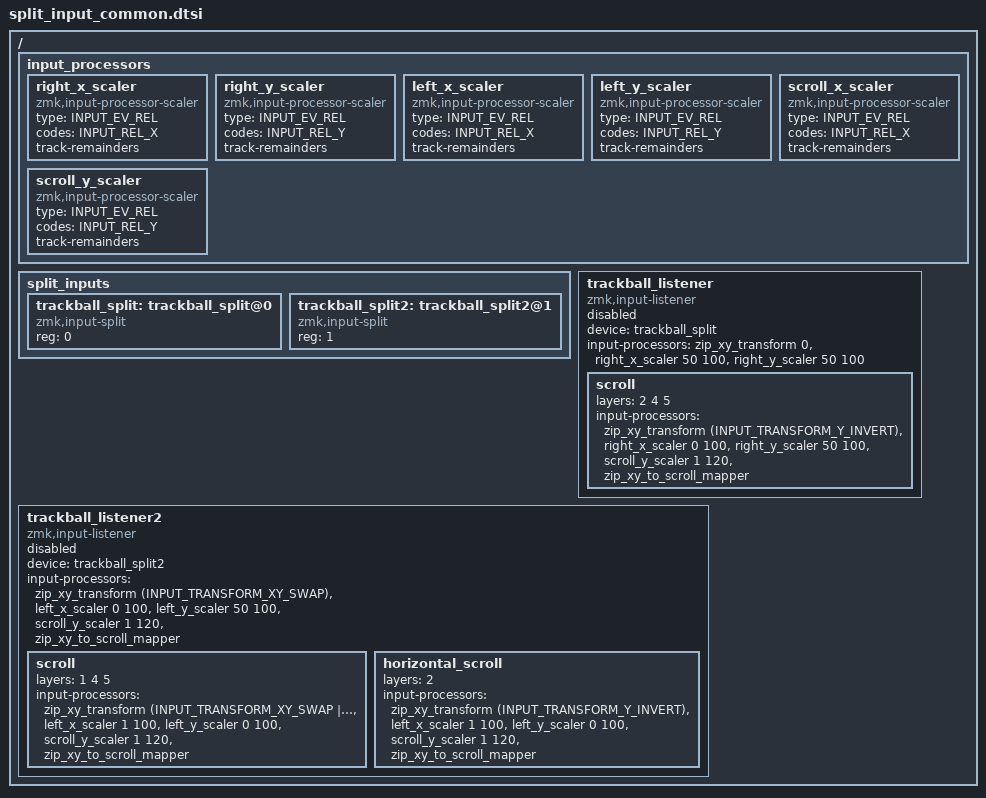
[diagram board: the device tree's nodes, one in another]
#include <dt-bindings/zmk/input_transform.h>
#include <input/processors.dtsi>
#include <zephyr/dt-bindings/input/input-event-codes.h>

#define WIN 1
#define SYMBOLS 2
#define NUMBERS 18
#define NAV 4
#define FUNCTION 5
#define BLUETOOTH 6
#define MOUSE 7
#define CLICK 8
#define SCRL 9
#define BIRO 10

/ {
  // カスタムInput Processors定義
  input_processors {
    // 右手トラックボール用（左45度+手前15度傾斜補正）
    right_x_scaler: right_x_scaler {
      compatible = "zmk,input-processor-scaler";
      #input-processor-cells = <2>;
      type = <INPUT_EV_REL>;
      codes = <INPUT_REL_X>;
      track-remainders;
    };
    
    right_y_scaler: right_y_scaler {
      compatible = "zmk,input-processor-scaler";
      #input-processor-cells = <2>;
      type = <INPUT_EV_REL>;
      codes = <INPUT_REL_Y>;
      track-remainders;
    };
    
    // 左手トラックボール用（同じ傾斜補正）
    left_x_scaler: left_x_scaler {
      compatible = "zmk,input-processor-scaler";
      #input-processor-cells = <2>;
      type = <INPUT_EV_REL>;
      codes = <INPUT_REL_X>;
      track-remainders;
    };
    
    left_y_scaler: left_y_scaler {
      compatible = "zmk,input-processor-scaler";
      #input-processor-cells = <2>;
      type = <INPUT_EV_REL>;
      codes = <INPUT_REL_Y>;
      track-remainders;
    };
    
    // スクロール用スケーラー（より敏感に）
    scroll_x_scaler: scroll_x_scaler {
      compatible = "zmk,input-processor-scaler";
      #input-processor-cells = <2>;
      type = <INPUT_EV_REL>;
      codes = <INPUT_REL_X>;
      track-remainders;
    };
    
    scroll_y_scaler: scroll_y_scaler {
      compatible = "zmk,input-processor-scaler";
      #input-processor-cells = <2>;
      type = <INPUT_EV_REL>;
      codes = <INPUT_REL_Y>;
      track-remainders;
    };
  };

  split_inputs {
    #address-cells = <1>;
    #size-cells = <0>;

    trackball_split: trackball_split@0 {
      compatible = "zmk,input-split";
      reg = <0>;
    };
    trackball_split2: trackball_split2@1 {
      compatible = "zmk,input-split";
      reg = <1>;
    };
  };

  // 右手：カーソル移動用トラックボール（傾斜補正付き）
  trackball_listener: trackball_listener {
    compatible = "zmk,input-listener";
    status = "disabled";
    device = <&trackball_split>;
    
    // デフォルト: 傾斜補正 + Y軸反転
    // 注意: 右手は左45度+手前15度傾斜
    input-processors = <&zip_xy_transform 0>,
                      <&right_x_scaler 50 100>,  // X軸: 70.7% → 100%補正
                      <&right_y_scaler 50 100>;  // Y軸: 96.6% → 100%補正
    
    // レイヤー1,2で縦スクロール（傾斜補正 + 感度調整）
    scroll {
      layers = <2 4 5>;
      input-processors = <&zip_xy_transform (INPUT_TRANSFORM_Y_INVERT)>,
                        <&right_x_scaler 0 100>,      // 傾斜補正
                        <&right_y_scaler 50 100>,      // 傾斜補正
                        <&scroll_y_scaler 1 120>,       // スクロール感度調整
                        <&zip_xy_to_scroll_mapper>;
    };
  };

  // 左手：スクロール用トラックボール（傾斜補正付き）
  trackball_listener2: trackball_listener2 {
    compatible = "zmk,input-listener";
    status = "disabled";
    device = <&trackball_split2>;
    
    // デフォルト（レイヤー0）：縦スクロール + 傾斜補正
    // 注意: 左手は右45度+手前15度傾斜（右手と線対称だが補正値は同じ）
    input-processors = <&zip_xy_transform (INPUT_TRANSFORM_XY_SWAP)>,
                      <&left_x_scaler 0 100>,       // X軸傾斜補正（スワップ後のX=元Y）
                      <&left_y_scaler 50 100>,       // Y軸傾斜補正（スワップ後のY=元X）
                      <&scroll_y_scaler 1 120>,       // スクロール感度調整
                      <&zip_xy_to_scroll_mapper>;
    
    // レイヤー1：縦スクロール（デフォルトと同じ、傾斜補正付き）
    scroll {
      layers = <1 4 5>;
      input-processors = <&zip_xy_transform (INPUT_TRANSFORM_XY_SWAP | INPUT_TRANSFORM_Y_INVERT)>,
                        <&left_x_scaler 1 100>,
                        <&left_y_scaler 0 100>,
                        <&scroll_y_scaler 1 120>,
                        <&zip_xy_to_scroll_mapper>;
    };
    
    // レイヤー2：横スクロール + 傾斜補正
    horizontal_scroll {
      layers = <2>;
      input-processors = <&zip_xy_transform (INPUT_TRANSFORM_Y_INVERT)>,
                        <&left_x_scaler 1 100>,
                        <&left_y_scaler 0 100>,
                        <&scroll_y_scaler 1 120>,
                        <&zip_xy_to_scroll_mapper>;
    };

  };
};
